# SMS0_TIFS_ECC_AGGR_0_ECC_AGGR register map
Vendor: Texas Instruments
Peripheral module from a debugger description file (folder am62P).
Registers are 32-bit, access not given, reset 0x0 unless marked. A register's access mark holds for its fields unless they carry their own. Offsets are as the file gives them; lines under a group give offsets from that group; [hi:lo] are bit positions; {n}, {i} and the like mark numbered series; 'fields as' and 'values as' point back to an identical list; <NAME> marks a mode.

## SMS0_TIFS_ECC_AGGR_0_ECC_AGGR
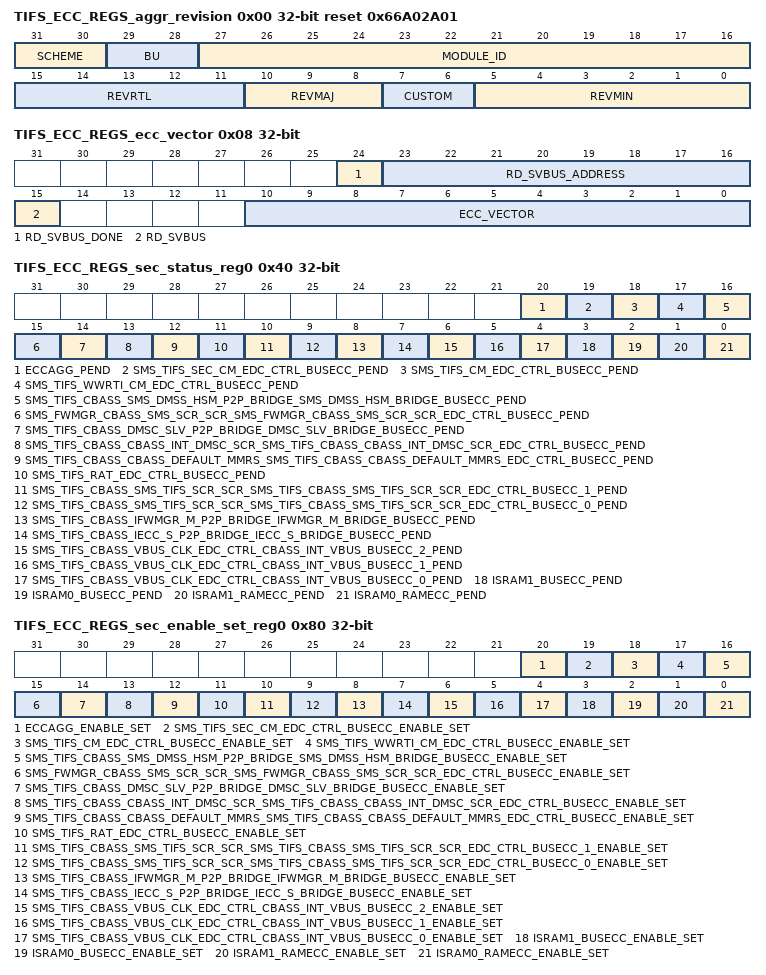
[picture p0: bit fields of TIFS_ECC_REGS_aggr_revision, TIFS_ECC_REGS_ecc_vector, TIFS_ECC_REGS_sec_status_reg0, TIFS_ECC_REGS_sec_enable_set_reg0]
0x00 TIFS_ECC_REGS_aggr_revision ro reset 0x66A02A01 — Revision parameters
  [31:30] SCHEME
  [29:28] BU
  [27:16] MODULE_ID
  [15:11] REVRTL — RTL version
  [10:8] REVMAJ — Major version
  [7:6] CUSTOM — Custom version
  [5:0] REVMIN — Minor version
0x08 TIFS_ECC_REGS_ecc_vector — ECC Vector Register
  [24] RD_SVBUS_DONE — Status to indicate if read on serial VBUS is complete, write of any value will clear this bit. (access R/W1TC)
  [23:16] RD_SVBUS_ADDRESS rw — Read address
  [15] RD_SVBUS — Write 1 to trigger a read on the serial VBUS (access R/W1TS)
  [10:0] ECC_VECTOR rw — Value written to select the corresponding ECC RAM for control or status
0x0C TIFS_ECC_REGS_misc_status ro reset 0x15 — Misc Status
  [10:0] NUM_RAMS — Indicates the number of RAMS serviced by the ECC aggregator
0x10 TIFS_ECC_REGS_reserved_svbus rw — Reference other documents that contain the ECC RAM wrapper and EDC controller serial vbus register sets.
  [31:0] DATA — Serial VBUS register data
0x3C TIFS_ECC_REGS_sec_eoi_reg — EOI Register
  [0] EOI_WR — EOI Register (access R/W1TS)
0x40 TIFS_ECC_REGS_sec_status_reg0 — Interrupt Status Register 0
  [20] ECCAGG_PEND — Interrupt Pending Status for eccagg_pend (access R/W1TS)
  [19] SMS_TIFS_SEC_CM_EDC_CTRL_BUSECC_PEND — Interrupt Pending Status for sms_tifs_sec_cm_edc_ctrl_busecc_pend (access R/W1TS)
  [18] SMS_TIFS_CM_EDC_CTRL_BUSECC_PEND — Interrupt Pending Status for sms_tifs_cm_edc_ctrl_busecc_pend (access R/W1TS)
  [17] SMS_TIFS_WWRTI_CM_EDC_CTRL_BUSECC_PEND — Interrupt Pending Status for sms_tifs_wwrti_cm_edc_ctrl_busecc_pend (access R/W1TS)
  [16] SMS_TIFS_CBASS_SMS_DMSS_HSM_P2P_BRIDGE_SMS_DMSS_HSM_BRIDGE_BUSECC_PEND — Interrupt Pending Status for sms_tifs_cbass_sms_dmss_hsm_p2p_bridge_sms_dmss_hsm_bridge_busecc_pend (access R/W1TS)
  [15] SMS_FWMGR_CBASS_SMS_SCR_SCR_SMS_FWMGR_CBASS_SMS_SCR_SCR_EDC_CTRL_BUSECC_PEND — Interrupt Pending Status for sms_fwmgr_cbass_sms_scr_scr_sms_fwmgr_cbass_sms_scr_scr_edc_ctrl_busecc_pend (access R/W1TS)
  [14] SMS_TIFS_CBASS_DMSC_SLV_P2P_BRIDGE_DMSC_SLV_BRIDGE_BUSECC_PEND — Interrupt Pending Status for sms_tifs_cbass_dmsc_slv_p2p_bridge_dmsc_slv_bridge_busecc_pend (access R/W1TS)
  [13] SMS_TIFS_CBASS_CBASS_INT_DMSC_SCR_SMS_TIFS_CBASS_CBASS_INT_DMSC_SCR_EDC_CTRL_BUSECC_PEND — Interrupt Pending Status for sms_tifs_cbass_cbass_int_dmsc_scr_sms_tifs_cbass_cbass_int_dmsc_scr_edc_ctrl_busecc_pend (access R/W1TS)
  [12] SMS_TIFS_CBASS_CBASS_DEFAULT_MMRS_SMS_TIFS_CBASS_CBASS_DEFAULT_MMRS_EDC_CTRL_BUSECC_PEND — Interrupt Pending Status for sms_tifs_cbass_cbass_default_mmrs_sms_tifs_cbass_cbass_default_mmrs_edc_ctrl_busecc_pend (access R/W1TS)
  [11] SMS_TIFS_RAT_EDC_CTRL_BUSECC_PEND — Interrupt Pending Status for sms_tifs_rat_edc_ctrl_busecc_pend (access R/W1TS)
  [10] SMS_TIFS_CBASS_SMS_TIFS_SCR_SCR_SMS_TIFS_CBASS_SMS_TIFS_SCR_SCR_EDC_CTRL_BUSECC_1_PEND — Interrupt Pending Status for sms_tifs_cbass_sms_tifs_scr_scr_sms_tifs_cbass_sms_tifs_scr_scr_edc_ctrl_busecc_1_pend (access R/W1TS)
  [9] SMS_TIFS_CBASS_SMS_TIFS_SCR_SCR_SMS_TIFS_CBASS_SMS_TIFS_SCR_SCR_EDC_CTRL_BUSECC_0_PEND — Interrupt Pending Status for sms_tifs_cbass_sms_tifs_scr_scr_sms_tifs_cbass_sms_tifs_scr_scr_edc_ctrl_busecc_0_pend (access R/W1TS)
  [8] SMS_TIFS_CBASS_IFWMGR_M_P2P_BRIDGE_IFWMGR_M_BRIDGE_BUSECC_PEND — Interrupt Pending Status for sms_tifs_cbass_Ifwmgr_m_p2p_bridge_Ifwmgr_m_bridge_busecc_pend (access R/W1TS)
  [7] SMS_TIFS_CBASS_IECC_S_P2P_BRIDGE_IECC_S_BRIDGE_BUSECC_PEND — Interrupt Pending Status for sms_tifs_cbass_Iecc_s_p2p_bridge_Iecc_s_bridge_busecc_pend (access R/W1TS)
  [6] SMS_TIFS_CBASS_VBUS_CLK_EDC_CTRL_CBASS_INT_VBUS_BUSECC_2_PEND — Interrupt Pending Status for sms_tifs_cbass_vbus_clk_edc_ctrl_cbass_int_vbus_busecc_2_pend (access R/W1TS)
  [5] SMS_TIFS_CBASS_VBUS_CLK_EDC_CTRL_CBASS_INT_VBUS_BUSECC_1_PEND — Interrupt Pending Status for sms_tifs_cbass_vbus_clk_edc_ctrl_cbass_int_vbus_busecc_1_pend (access R/W1TS)
  [4] SMS_TIFS_CBASS_VBUS_CLK_EDC_CTRL_CBASS_INT_VBUS_BUSECC_0_PEND — Interrupt Pending Status for sms_tifs_cbass_vbus_clk_edc_ctrl_cbass_int_vbus_busecc_0_pend (access R/W1TS)
  [3] ISRAM1_BUSECC_PEND — Interrupt Pending Status for Isram1_busecc_pend (access R/W1TS)
  [2] ISRAM0_BUSECC_PEND — Interrupt Pending Status for Isram0_busecc_pend (access R/W1TS)
  [1] ISRAM1_RAMECC_PEND — Interrupt Pending Status for Isram1_ramecc_pend (access R/W1TS)
  [0] ISRAM0_RAMECC_PEND — Interrupt Pending Status for Isram0_ramecc_pend (access R/W1TS)
0x80 TIFS_ECC_REGS_sec_enable_set_reg0 — Interrupt Enable Set Register 0
  [20] ECCAGG_ENABLE_SET — Interrupt Enable Set Register for eccagg_pend (access R/W1TS)
  [19] SMS_TIFS_SEC_CM_EDC_CTRL_BUSECC_ENABLE_SET — Interrupt Enable Set Register for sms_tifs_sec_cm_edc_ctrl_busecc_pend (access R/W1TS)
  [18] SMS_TIFS_CM_EDC_CTRL_BUSECC_ENABLE_SET — Interrupt Enable Set Register for sms_tifs_cm_edc_ctrl_busecc_pend (access R/W1TS)
  [17] SMS_TIFS_WWRTI_CM_EDC_CTRL_BUSECC_ENABLE_SET — Interrupt Enable Set Register for sms_tifs_wwrti_cm_edc_ctrl_busecc_pend (access R/W1TS)
  [16] SMS_TIFS_CBASS_SMS_DMSS_HSM_P2P_BRIDGE_SMS_DMSS_HSM_BRIDGE_BUSECC_ENABLE_SET — Interrupt Enable Set Register for sms_tifs_cbass_sms_dmss_hsm_p2p_bridge_sms_dmss_hsm_bridge_busecc_pend (access R/W1TS)
  [15] SMS_FWMGR_CBASS_SMS_SCR_SCR_SMS_FWMGR_CBASS_SMS_SCR_SCR_EDC_CTRL_BUSECC_ENABLE_SET — Interrupt Enable Set Register for sms_fwmgr_cbass_sms_scr_scr_sms_fwmgr_cbass_sms_scr_scr_edc_ctrl_busecc_pend (access R/W1TS)
  [14] SMS_TIFS_CBASS_DMSC_SLV_P2P_BRIDGE_DMSC_SLV_BRIDGE_BUSECC_ENABLE_SET — Interrupt Enable Set Register for sms_tifs_cbass_dmsc_slv_p2p_bridge_dmsc_slv_bridge_busecc_pend (access R/W1TS)
  [13] SMS_TIFS_CBASS_CBASS_INT_DMSC_SCR_SMS_TIFS_CBASS_CBASS_INT_DMSC_SCR_EDC_CTRL_BUSECC_ENABLE_SET — Interrupt Enable Set Register for sms_tifs_cbass_cbass_int_dmsc_scr_sms_tifs_cbass_cbass_int_dmsc_scr_edc_ctrl_busecc_pend (access R/W1TS)
  [12] SMS_TIFS_CBASS_CBASS_DEFAULT_MMRS_SMS_TIFS_CBASS_CBASS_DEFAULT_MMRS_EDC_CTRL_BUSECC_ENABLE_SET — Interrupt Enable Set Register for sms_tifs_cbass_cbass_default_mmrs_sms_tifs_cbass_cbass_default_mmrs_edc_ctrl_busecc_pend (access R/W1TS)
  [11] SMS_TIFS_RAT_EDC_CTRL_BUSECC_ENABLE_SET — Interrupt Enable Set Register for sms_tifs_rat_edc_ctrl_busecc_pend (access R/W1TS)
  [10] SMS_TIFS_CBASS_SMS_TIFS_SCR_SCR_SMS_TIFS_CBASS_SMS_TIFS_SCR_SCR_EDC_CTRL_BUSECC_1_ENABLE_SET — Interrupt Enable Set Register for sms_tifs_cbass_sms_tifs_scr_scr_sms_tifs_cbass_sms_tifs_scr_scr_edc_ctrl_busecc_1_pend (access R/W1TS)
  [9] SMS_TIFS_CBASS_SMS_TIFS_SCR_SCR_SMS_TIFS_CBASS_SMS_TIFS_SCR_SCR_EDC_CTRL_BUSECC_0_ENABLE_SET — Interrupt Enable Set Register for sms_tifs_cbass_sms_tifs_scr_scr_sms_tifs_cbass_sms_tifs_scr_scr_edc_ctrl_busecc_0_pend (access R/W1TS)
  [8] SMS_TIFS_CBASS_IFWMGR_M_P2P_BRIDGE_IFWMGR_M_BRIDGE_BUSECC_ENABLE_SET — Interrupt Enable Set Register for sms_tifs_cbass_Ifwmgr_m_p2p_bridge_Ifwmgr_m_bridge_busecc_pend (access R/W1TS)
  [7] SMS_TIFS_CBASS_IECC_S_P2P_BRIDGE_IECC_S_BRIDGE_BUSECC_ENABLE_SET — Interrupt Enable Set Register for sms_tifs_cbass_Iecc_s_p2p_bridge_Iecc_s_bridge_busecc_pend (access R/W1TS)
  [6] SMS_TIFS_CBASS_VBUS_CLK_EDC_CTRL_CBASS_INT_VBUS_BUSECC_2_ENABLE_SET — Interrupt Enable Set Register for sms_tifs_cbass_vbus_clk_edc_ctrl_cbass_int_vbus_busecc_2_pend (access R/W1TS)
  [5] SMS_TIFS_CBASS_VBUS_CLK_EDC_CTRL_CBASS_INT_VBUS_BUSECC_1_ENABLE_SET — Interrupt Enable Set Register for sms_tifs_cbass_vbus_clk_edc_ctrl_cbass_int_vbus_busecc_1_pend (access R/W1TS)
  [4] SMS_TIFS_CBASS_VBUS_CLK_EDC_CTRL_CBASS_INT_VBUS_BUSECC_0_ENABLE_SET — Interrupt Enable Set Register for sms_tifs_cbass_vbus_clk_edc_ctrl_cbass_int_vbus_busecc_0_pend (access R/W1TS)
  [3] ISRAM1_BUSECC_ENABLE_SET — Interrupt Enable Set Register for Isram1_busecc_pend (access R/W1TS)
  [2] ISRAM0_BUSECC_ENABLE_SET — Interrupt Enable Set Register for Isram0_busecc_pend (access R/W1TS)
  [1] ISRAM1_RAMECC_ENABLE_SET — Interrupt Enable Set Register for Isram1_ramecc_pend (access R/W1TS)
  [0] ISRAM0_RAMECC_ENABLE_SET — Interrupt Enable Set Register for Isram0_ramecc_pend (access R/W1TS)
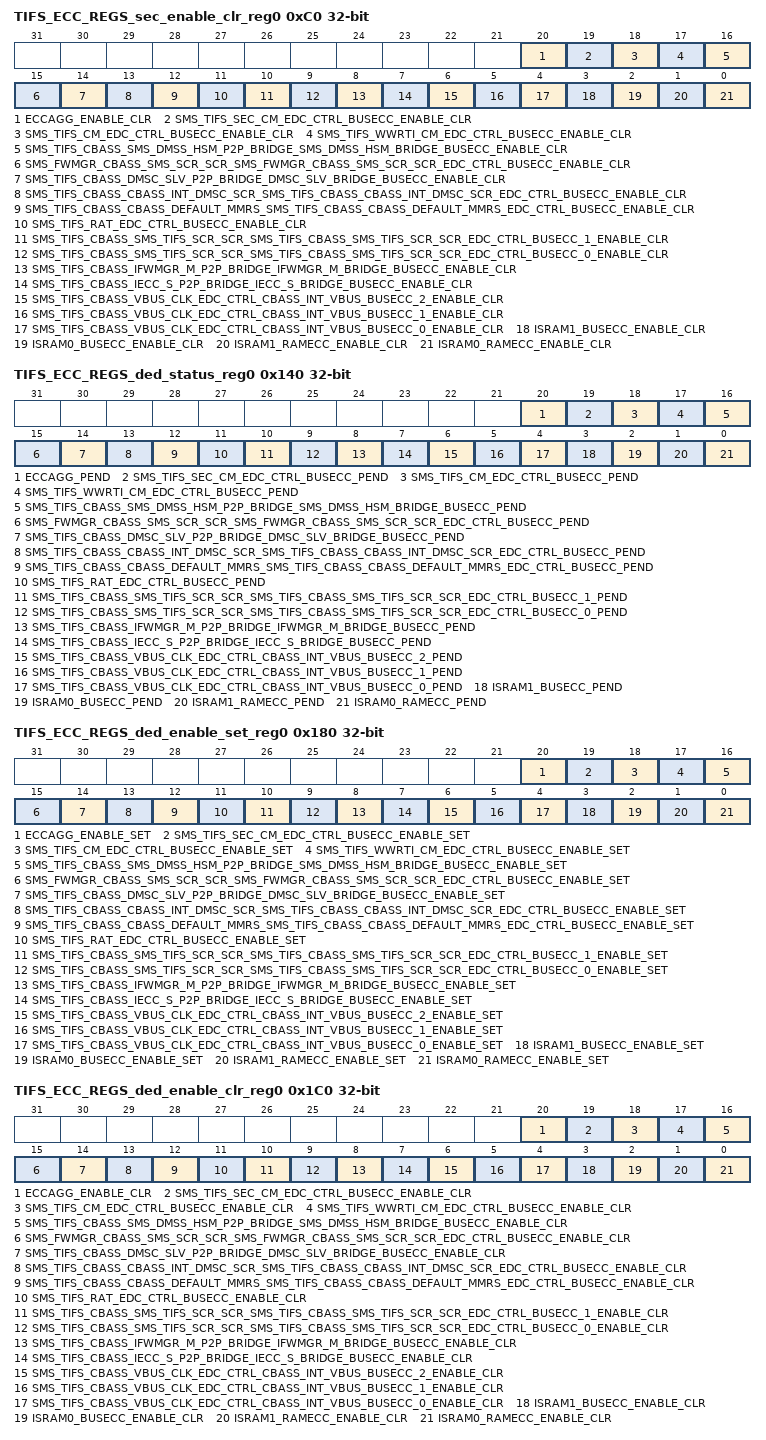
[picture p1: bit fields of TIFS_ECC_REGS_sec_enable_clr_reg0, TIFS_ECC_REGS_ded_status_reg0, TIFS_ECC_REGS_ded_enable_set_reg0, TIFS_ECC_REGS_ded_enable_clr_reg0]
0xC0 TIFS_ECC_REGS_sec_enable_clr_reg0 — Interrupt Enable Clear Register 0
  [20] ECCAGG_ENABLE_CLR — Interrupt Enable Clear Register for eccagg_pend (access R/W1TC)
  [19] SMS_TIFS_SEC_CM_EDC_CTRL_BUSECC_ENABLE_CLR — Interrupt Enable Clear Register for sms_tifs_sec_cm_edc_ctrl_busecc_pend (access R/W1TC)
  [18] SMS_TIFS_CM_EDC_CTRL_BUSECC_ENABLE_CLR — Interrupt Enable Clear Register for sms_tifs_cm_edc_ctrl_busecc_pend (access R/W1TC)
  [17] SMS_TIFS_WWRTI_CM_EDC_CTRL_BUSECC_ENABLE_CLR — Interrupt Enable Clear Register for sms_tifs_wwrti_cm_edc_ctrl_busecc_pend (access R/W1TC)
  [16] SMS_TIFS_CBASS_SMS_DMSS_HSM_P2P_BRIDGE_SMS_DMSS_HSM_BRIDGE_BUSECC_ENABLE_CLR — Interrupt Enable Clear Register for sms_tifs_cbass_sms_dmss_hsm_p2p_bridge_sms_dmss_hsm_bridge_busecc_pend (access R/W1TC)
  [15] SMS_FWMGR_CBASS_SMS_SCR_SCR_SMS_FWMGR_CBASS_SMS_SCR_SCR_EDC_CTRL_BUSECC_ENABLE_CLR — Interrupt Enable Clear Register for sms_fwmgr_cbass_sms_scr_scr_sms_fwmgr_cbass_sms_scr_scr_edc_ctrl_busecc_pend (access R/W1TC)
  [14] SMS_TIFS_CBASS_DMSC_SLV_P2P_BRIDGE_DMSC_SLV_BRIDGE_BUSECC_ENABLE_CLR — Interrupt Enable Clear Register for sms_tifs_cbass_dmsc_slv_p2p_bridge_dmsc_slv_bridge_busecc_pend (access R/W1TC)
  [13] SMS_TIFS_CBASS_CBASS_INT_DMSC_SCR_SMS_TIFS_CBASS_CBASS_INT_DMSC_SCR_EDC_CTRL_BUSECC_ENABLE_CLR — Interrupt Enable Clear Register for sms_tifs_cbass_cbass_int_dmsc_scr_sms_tifs_cbass_cbass_int_dmsc_scr_edc_ctrl_busecc_pend (access R/W1TC)
  [12] SMS_TIFS_CBASS_CBASS_DEFAULT_MMRS_SMS_TIFS_CBASS_CBASS_DEFAULT_MMRS_EDC_CTRL_BUSECC_ENABLE_CLR — Interrupt Enable Clear Register for sms_tifs_cbass_cbass_default_mmrs_sms_tifs_cbass_cbass_default_mmrs_edc_ctrl_busecc_pend (access R/W1TC)
  [11] SMS_TIFS_RAT_EDC_CTRL_BUSECC_ENABLE_CLR — Interrupt Enable Clear Register for sms_tifs_rat_edc_ctrl_busecc_pend (access R/W1TC)
  [10] SMS_TIFS_CBASS_SMS_TIFS_SCR_SCR_SMS_TIFS_CBASS_SMS_TIFS_SCR_SCR_EDC_CTRL_BUSECC_1_ENABLE_CLR — Interrupt Enable Clear Register for sms_tifs_cbass_sms_tifs_scr_scr_sms_tifs_cbass_sms_tifs_scr_scr_edc_ctrl_busecc_1_pend (access R/W1TC)
  [9] SMS_TIFS_CBASS_SMS_TIFS_SCR_SCR_SMS_TIFS_CBASS_SMS_TIFS_SCR_SCR_EDC_CTRL_BUSECC_0_ENABLE_CLR — Interrupt Enable Clear Register for sms_tifs_cbass_sms_tifs_scr_scr_sms_tifs_cbass_sms_tifs_scr_scr_edc_ctrl_busecc_0_pend (access R/W1TC)
  [8] SMS_TIFS_CBASS_IFWMGR_M_P2P_BRIDGE_IFWMGR_M_BRIDGE_BUSECC_ENABLE_CLR — Interrupt Enable Clear Register for sms_tifs_cbass_Ifwmgr_m_p2p_bridge_Ifwmgr_m_bridge_busecc_pend (access R/W1TC)
  [7] SMS_TIFS_CBASS_IECC_S_P2P_BRIDGE_IECC_S_BRIDGE_BUSECC_ENABLE_CLR — Interrupt Enable Clear Register for sms_tifs_cbass_Iecc_s_p2p_bridge_Iecc_s_bridge_busecc_pend (access R/W1TC)
  [6] SMS_TIFS_CBASS_VBUS_CLK_EDC_CTRL_CBASS_INT_VBUS_BUSECC_2_ENABLE_CLR — Interrupt Enable Clear Register for sms_tifs_cbass_vbus_clk_edc_ctrl_cbass_int_vbus_busecc_2_pend (access R/W1TC)
  [5] SMS_TIFS_CBASS_VBUS_CLK_EDC_CTRL_CBASS_INT_VBUS_BUSECC_1_ENABLE_CLR — Interrupt Enable Clear Register for sms_tifs_cbass_vbus_clk_edc_ctrl_cbass_int_vbus_busecc_1_pend (access R/W1TC)
  [4] SMS_TIFS_CBASS_VBUS_CLK_EDC_CTRL_CBASS_INT_VBUS_BUSECC_0_ENABLE_CLR — Interrupt Enable Clear Register for sms_tifs_cbass_vbus_clk_edc_ctrl_cbass_int_vbus_busecc_0_pend (access R/W1TC)
  [3] ISRAM1_BUSECC_ENABLE_CLR — Interrupt Enable Clear Register for Isram1_busecc_pend (access R/W1TC)
  [2] ISRAM0_BUSECC_ENABLE_CLR — Interrupt Enable Clear Register for Isram0_busecc_pend (access R/W1TC)
  [1] ISRAM1_RAMECC_ENABLE_CLR — Interrupt Enable Clear Register for Isram1_ramecc_pend (access R/W1TC)
  [0] ISRAM0_RAMECC_ENABLE_CLR — Interrupt Enable Clear Register for Isram0_ramecc_pend (access R/W1TC)
0x13C TIFS_ECC_REGS_ded_eoi_reg — EOI Register
  [0] EOI_WR — EOI Register (access R/W1TS)
0x140 TIFS_ECC_REGS_ded_status_reg0 — Interrupt Status Register 0
  fields as TIFS_ECC_REGS_sec_status_reg0
0x180 TIFS_ECC_REGS_ded_enable_set_reg0 — Interrupt Enable Set Register 0
  fields as TIFS_ECC_REGS_sec_enable_set_reg0
0x1C0 TIFS_ECC_REGS_ded_enable_clr_reg0 — Interrupt Enable Clear Register 0
  fields as TIFS_ECC_REGS_sec_enable_clr_reg0
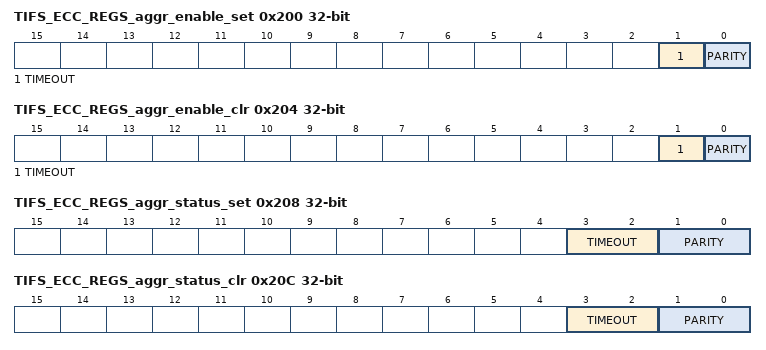
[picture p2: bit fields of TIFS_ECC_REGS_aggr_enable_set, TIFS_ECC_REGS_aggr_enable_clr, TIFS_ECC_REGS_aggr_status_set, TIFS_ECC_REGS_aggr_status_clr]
0x200 TIFS_ECC_REGS_aggr_enable_set — AGGR interrupt enable set Register
  [1] TIMEOUT — interrupt enable set for svbus timeout errors (access R/W1TS)
  [0] PARITY — interrupt enable set for parity errors (access R/W1TS)
0x204 TIFS_ECC_REGS_aggr_enable_clr — AGGR interrupt enable clear Register
  [1] TIMEOUT — interrupt enable clear for svbus timeout errors (access R/W1TC)
  [0] PARITY — interrupt enable clear for parity errors (access R/W1TC)
0x208 TIFS_ECC_REGS_aggr_status_set — AGGR interrupt status set Register
  [3:2] TIMEOUT — interrupt status set for svbus timeout errors (access R/WI)
  [1:0] PARITY — interrupt status set for parity errors (access R/WI)
0x20C TIFS_ECC_REGS_aggr_status_clr — AGGR interrupt status clear Register
  [3:2] TIMEOUT — interrupt status clear for svbus timeout errors (access R/WD)
  [1:0] PARITY — interrupt status clear for parity errors (access R/WD)
